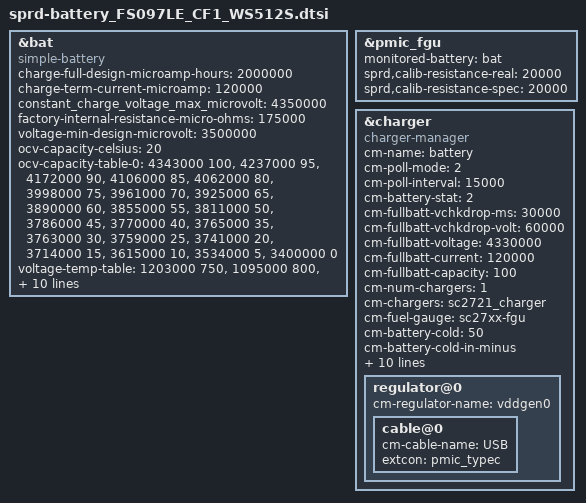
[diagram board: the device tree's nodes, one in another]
/*
* Copyright (C) 2015 Spreadtrum Communication Incorporated
*		http://www.spreadtrum.com/
*
* This program is free software; you can redistribute it and/or modify
* it under the terms of the GNU General Public License version 2 as
* published by the Free Software Foundation.
*/

/* This is the zyt battery default DTS */

&bat {
		compatible = "simple-battery";
		charge-full-design-microamp-hours = <2000000>;
		charge-term-current-microamp = <120000>;
		constant_charge_voltage_max_microvolt = <4350000>;
		factory-internal-resistance-micro-ohms = <175000>;
		voltage-min-design-microvolt = <3500000>;
		ocv-capacity-celsius = <20>;
		ocv-capacity-table-0 = <4343000 100>, <4237000 95>, <4172000 90>,
					<4106000 85>, <4062000 80>, <3998000 75>,
					<3961000 70>, <3925000 65>, <3890000 60>,
					<3855000 55>, <3811000 50>, <3786000 45>,
					<3770000 40>, <3765000 35>, <3763000 30>,
					<3759000 25>, <3741000 20>, <3714000 15>,
					<3615000 10>, <3534000 5>, <3400000 0>;
		voltage-temp-table = <1203000 750>,<1095000 800>, <986000 850>, <878000 900>,
			  <775000 950>, <678000 1000>, <590000 1050>,
			  <510000 1100>, <440000 1150>, <378000 1200>,
			  <324000 1250>, <278000 1300>, <238000 1350>,
			  <204000 1400>, <175000 1450>, <150000 1500>,
			  <129000 1550>, <111000 1600>, <96000 1650>;
		charge-sdp-current-microamp = <500000 500000>;
		charge-dcp-current-microamp = <1000000 1500000>;
		charge-cdp-current-microamp = <1000000 1500000>;
		charge-unknown-current-microamp = <500000 500000>;
	};
	
&pmic_fgu {
		  monitored-battery = <&bat>;
		  sprd,calib-resistance-real = <20000>;
		  sprd,calib-resistance-spec = <20000>;
	};
	
&charger{
		compatible = "charger-manager";
		cm-name = "battery";
		cm-poll-mode = <2>;
		cm-poll-interval = <15000>;
		cm-battery-stat = <2>;

		cm-fullbatt-vchkdrop-ms = <30000>;
		cm-fullbatt-vchkdrop-volt = <60000>;
		cm-fullbatt-voltage = <4330000>;
		cm-fullbatt-current = <120000>;
		cm-fullbatt-capacity = <100>;

		cm-num-chargers = <1>;
		cm-chargers = "sc2721_charger";
		cm-fuel-gauge = "sc27xx-fgu";

		/* in deci centigrade */
		cm-battery-cold = <50>;
		cm-battery-cold-in-minus;
		cm-battery-hot = <550>;
		cm-battery-temp-diff = <50>;

		/* Allow charging for 6hr */
		cm-charging-max = <21600000>;
		/* recovery charging after stop charging 3hr */
		cm-discharging-max = <10800000>;

		/* the interval to feed charger watchdog */
		cm-wdt-interval = <0>;

		/* drop voltage in microVolts to allow shutdown */
		cm-shutdown-voltage = <3100000>;

		/* when 99% of the time is exceeded, it will be forced to 100% */
		cm-tickle-time-out = <500>;

		/* how much time to allow capacity change */
		cm-one-cap-time = <30>;

		/* when the safe charging voltage is exceeded, stop charging */
		cm-charge-voltage-max = <6100000>;
		/* drop voltage in microVolts to restart charging */
		cm-charge-voltage-drop = <250000>;
		
		/*
		cm-jeita-temp-table = <1000 1030 2000000 4400000>, <1150 1180 2000000 4400000>,
				<1450 1420 2000000 4400000>, <1600 1570 2000000 4400000>;
		*/

		regulator@0 {
			cm-regulator-name = "vddgen0";
			cable@0 {
				cm-cable-name = "USB";
				extcon = <&pmic_typec>;
			};
		};
	};

